# SYS_208.0 register map
Vendor: Texas Instruments
Peripheral module from a debugger description file (folder msp430).
Registers are 16-bit, read-write, no defined reset value unless marked. A register's access mark holds for its fields unless they carry their own. Offsets are as the file gives them; lines under a group give offsets from that group; [hi:lo] are bit positions; {n}, {i} and the like mark numbered series; 'fields as' and 'values as' point back to an identical list; <NAME> marks a mode.

## SYS
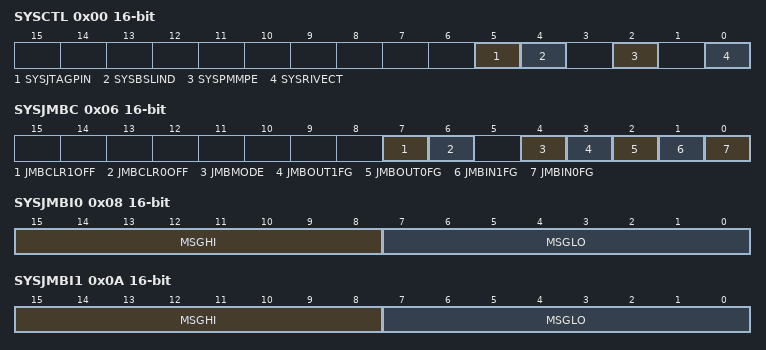
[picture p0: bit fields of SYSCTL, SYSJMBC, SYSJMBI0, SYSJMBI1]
0x00 SYSCTL access per field — System Control
  [5] SYSJTAGPIN rw — Dedicated JTAG pins enable
    0=SHARED (Shared JTAG pins (JTAG mode selectable using SBW sequence)); 1=DEDICATED (Dedicated JTAG pins (explicit 4-wire JTAG mode selection))
  [4] SYSBSLIND ro — BSL entry indication
    0=No BSL entry sequence detected; 1=BSL entry sequence detected
  [2] SYSPMMPE rw — PMM access protect
    0=Access from anywhere in memory; 1=Access only from the BSL segments
  [0] SYSRIVECT rw — RAM-based interrupt vectors
    0=FRAM (Interrupt vectors generated with end address TOP of lower 64K FRAM FFFFh); 1=RAM (Interrupt vectors generated with end address TOP of RAM, when RAM available)
0x06 SYSJMBC access per field — JTAG Mailbox Control
  [7] JMBCLR1OFF rw — Incoming JTAG Mailbox 1 flag auto-clear disable
    0=JMBIN1FG cleared on read of JMB1IN register; 1=JMBIN1FG cleared by software
  [6] JMBCLR0OFF rw — Incoming JTAG Mailbox 0 flag auto-clear disable
    0=JMBIN0FG cleared on read of JMB0IN register; 1=JMBIN0FG cleared by software
  [4] JMBMODE rw — Operation mode of JMB
    0=16BIT (16-bit transfers using JMBO0 and JMBI0 only); 1=32BIT (32-bit transfers using JMBO0 with JMBO1 and JMBI0 with JMBI1)
  [3] JMBOUT1FG ro — Outgoing JTAG Mailbox 1 flag
    0=JMBO1 is not ready to receive new data; 1=JMBO1 is ready to receive new data
  [2] JMBOUT0FG ro — Outgoing JTAG Mailbox 0 flag
    0=JMBO0 is not ready to receive new data; 1=JMBO0 is ready to receive new data
  [1] JMBIN1FG rw — Incoming JTAG Mailbox 1 flag
    0=JMBI1 has no new data; 1=JMBI1 has new data available
  [0] JMBIN0FG rw — Incoming JTAG Mailbox 0 flag
    0=JMBI0 has no new data; 1=JMBI0 has new data available
0x08 SYSJMBI0 — JTAG Mailbox Input
  [15:8] MSGHI — JTAG mailbox incoming message high byte
  [7:0] MSGLO — JTAG mailbox incoming message low byte
0x0A SYSJMBI1 — JTAG Mailbox Input
  fields as SYSJMBI0
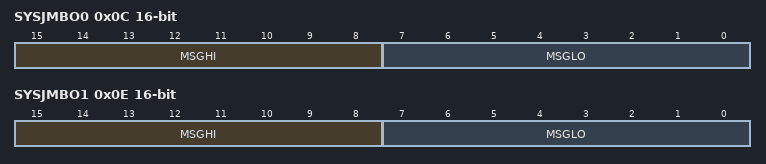
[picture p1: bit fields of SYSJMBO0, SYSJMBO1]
0x0C SYSJMBO0 — JTAG Mailbox Output
  [15:8] MSGHI — JTAG mailbox outgoing message high byte
  [7:0] MSGLO — JTAG mailbox outgoing message low byte
0x0E SYSJMBO1 — JTAG Mailbox Output
  fields as SYSJMBO0
0x1A SYSUNIV ro — User NMI Vector Generator
  [15:0] SYSUNIV — User NMI vector
    0=NONE (No interrupt pending); 2=NMIIFG (NMIIFG NMI pin); 4=OFIFG (OFIFG oscillator fault)
0x1C SYSSNIV ro — System NMI Vector Generator
  [15:0] SYSSNIV — System NMI vector
    0=NONE (No interrupt pending); 4=UBDIFG (Uncorrectable FRAM bit error detection); 6=ACCTEIFG (FRAM Access Time Error); 8=MPUSEGPIFG (MPUSEGPIFG encapsulated IP memory segment violation); 10=MPUSEGIIFG (MPUSEGIIFG information memory segment violation); 12=MPUSEG1IFG (MPUSEG1IFG segment 1 memory violation); 14=MPUSEG2IFG (MPUSEG2IFG segment 2 memory violation); 16=MPUSEG3IFG (MPUSEG3IFG segment 3 memory violation); 18=VMAIFG (VMAIFG Vacant memory access); 20=JMBINIFG (JMBINIFG JTAG mailbox input); 22=JMBOUTIFG (JMBOUTIFG JTAG mailbox output); 24=CBDIFG (Correctable FRAM bit error detection); 26=WPROT (FRAM write protection detection); 28=LEATO (LEA time-out fault); 30=LEACMD (LEA command fault)
0x1E SYSRSTIV ro — Reset Vector Generator
  [15:0] SYSRSTIV — Reset interrupt vector
    0=NONE (No interrupt pending); 2=BOR (Brownout); 4=RSTNMI (RSTIFG RST/NMI); 6=PMMSWBOR (PMMSWBOR software BOR); 8=LPM5WU (LPMx.5 wakeup); 10=SECYV (Security violation); 14=SVSHIFG (SVSHIFG SVSH event); 20=PMMSWPOR (PMMSWPOR software POR); 22=WDTIFG (WDTIFG watchdog timeout); 24=WDTPW (WDTPW watchdog password violation); 26=FRCTLPW (FRCTLPW password violation); 28=UBDIFG (Uncorrectable FRAM bit error detection); 30=PERF (Peripheral area fetch); 32=PMMPW (PMM password violation); 34=MPUPW (MPU password violation); 36=CSPW (CS password violation); 38=MPUSEGPIFG (MPUSEGPIFG encapsulated IP memory segment violation); 40=MPUSEGIIFG (MPUSEGIIFG information memory segment violation); 42=MPUSEG1IFG (MPUSEG1IFG segment 1 memory violation); 44=MPUSEG2IFG (MPUSEG2IFG segment 2 memory violation); 46=MPUSEG3IFG (MPUSEG3IFG segment 3 memory violation)
